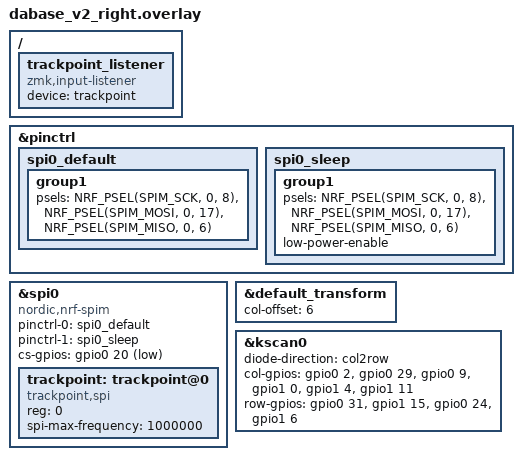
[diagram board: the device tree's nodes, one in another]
/*
 * Copyright (c) 2020 The ZMK Contributors
 *
 * SPDX-License-Identifier: MIT
 */

#include "dabase_v2.dtsi"

&pinctrl {
    spi0_default: spi0_default {
        group1 {
            psels = <NRF_PSEL(SPIM_SCK, 0, 8)>,
                    <NRF_PSEL(SPIM_MOSI, 0, 17)>,
                    <NRF_PSEL(SPIM_MISO, 0, 6)>;
        };
    };
    spi0_sleep: spi0_sleep {
        group1 {
            psels = <NRF_PSEL(SPIM_SCK, 0, 8)>,
                    <NRF_PSEL(SPIM_MOSI, 0, 17)>,
                    <NRF_PSEL(SPIM_MISO, 0, 6)>;
            low-power-enable;
        };
    };
};

&spi0 {
    status = "okay";
    compatible = "nordic,nrf-spim";
    pinctrl-0 = <&spi0_default>;
    pinctrl-1 = <&spi0_sleep>;
    pinctrl-names = "default", "sleep";
    cs-gpios = <&gpio0 20 GPIO_ACTIVE_LOW>;

    trackpoint: trackpoint@0 {
        compatible = "trackpoint,spi";
        reg = <0>;
        spi-max-frequency = <1000000>;
    };
};

/ {
    trackpoint_listener {
        compatible = "zmk,input-listener";
        device = <&trackpoint>;
    };
};

&default_transform {
    col-offset = <6>;
};

&kscan0 {
    diode-direction = "col2row";
    col-gpios
        = <&gpio0 2  GPIO_ACTIVE_HIGH>
        , <&gpio0 29 GPIO_ACTIVE_HIGH>
        , <&gpio0 9  GPIO_ACTIVE_HIGH>
        , <&gpio1 0  GPIO_ACTIVE_HIGH>
        , <&gpio1 4  GPIO_ACTIVE_HIGH>
        , <&gpio1 11 GPIO_ACTIVE_HIGH>
    ;

    row-gpios
        = <&gpio0 31 (GPIO_ACTIVE_HIGH | GPIO_PULL_DOWN)>
        , <&gpio1 15 (GPIO_ACTIVE_HIGH | GPIO_PULL_DOWN)>
        , <&gpio0 24 (GPIO_ACTIVE_HIGH | GPIO_PULL_DOWN)>
        , <&gpio1 6  (GPIO_ACTIVE_HIGH | GPIO_PULL_DOWN)>
    ;
};
